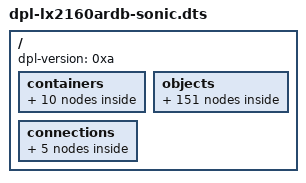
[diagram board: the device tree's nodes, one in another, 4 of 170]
/*
 * Copyright 2018-2019 NXP
 *
 * Redistribution and use in source and binary forms, with or without
 * modification, are permitted provided that the following conditions are met:
 *   * Redistributions of source code must retain the above copyright
 *     notice, this list of conditions and the following disclaimer.
 *   * Redistributions in binary form must reproduce the above copyright
 *     notice, this list of conditions and the following disclaimer in the
 *     documentation and/or other materials provided with the distribution.
 *   * Neither the name of the above-listed copyright holders nor the
 *     names of any contributors may be used to endorse or promote products
 *     derived from this software without specific prior written permission.
 *
 * THIS SOFTWARE IS PROVIDED BY THE COPYRIGHT HOLDERS AND CONTRIBUTORS "AS IS"
 * AND ANY EXPRESS OR IMPLIED WARRANTIES, INCLUDING, BUT NOT LIMITED TO, THE
 * IMPLIED WARRANTIES OF MERCHANTABILITY AND FITNESS FOR A PARTICULAR PURPOSE
 * ARE DISCLAIMED. IN NO EVENT SHALL THE COPYRIGHT HOLDERS OR CONTRIBUTORS BE
 * LIABLE FOR ANY DIRECT, INDIRECT, INCIDENTAL, SPECIAL, EXEMPLARY, OR
 * CONSEQUENTIAL DAMAGES (INCLUDING, BUT NOT LIMITED TO, PROCUREMENT OF
 * SUBSTITUTE GOODS OR SERVICES; LOSS OF USE, DATA, OR PROFITS; OR BUSINESS
 * INTERRUPTION) HOWEVER CAUSED AND ON ANY THEORY OF LIABILITY, WHETHER IN
 * CONTRACT, STRICT LIABILITY, OR TORT (INCLUDING NEGLIGENCE OR OTHERWISE)
 * ARISING IN ANY WAY OUT OF THE USE OF THIS SOFTWARE, EVEN IF ADVISED OF THE
 * POSSIBILITY OF SUCH DAMAGE.
 */

/*
 * LX2160ARDB DPL for SONiC (SerDes 19_5_2), derived from NXP mc-utils
 * dpl-eth.19.dts (lf-6.18.37-2.1.0). Changes:
 *   - dpni@2..4 added for dpmac@18 (RGMII 1G) and dpmac@3/@4 (AQR107 10GBASE-T);
 *     dpni@0 -> dpmac@17 and dpni@1 -> dpmac@2 are unchanged.
 *   - dpbp 0..5 (one buffer pool per DPNI) and dpcon 0..79 (up to 16 channels
 *     per DPNI on 16 cores), so every interface gets its full set.
 * Generated by scripts/mk-dpl.py; edit that, not this file.
 */
/dts-v1/;

/ {
	dpl-version = <0xa>;
	/*****************************************************************
	 * Containers
	 *****************************************************************/
	containers {
		dprc@1 {
			parent = "none";
			options = "DPRC_CFG_OPT_SPAWN_ALLOWED", "DPRC_CFG_OPT_ALLOC_ALLOWED", "DPRC_CFG_OPT_IRQ_CFG_ALLOWED";
			objects {
				/* ------------ DPNIs --------------*/
				obj_set@dpni {
					type = "dpni";
					ids = <0x0 0x1 0x2 0x3 0x4>;
				};


				/* ------------ DPMACs --------------*/
				obj_set@dpmac {
					type = "dpmac";
					ids = <0x2 0x3 0x4 0x5 0x6 0x11 0x12>;
				};


				/* ------------ DPBPs --------------*/
				obj_set@dpbp {
					type = "dpbp";
					ids = <0x0 0x1 0x2 0x3 0x4 0x5>;
				};

				/* ------------ DPIOs --------------*/
				obj_set@dpio {
					type = "dpio";
					ids = <0x0 0x1 0x2 0x3 0x4 0x5 0x6 0x7 0x8 0x9 0xa 0xb 0xc 0xd 0xe 0xf>;
				};

				/* ------------ DPMCPs --------------*/
				obj_set@dpmcp {
					type = "dpmcp";
					ids = <0x1 0x2 0x3 0x4 0x5 0x6 0x7 0x8 0x9 0xa 0xb 0xc 0xd 0xe 0xf 0x10 0x11 0x12 0x13 0x14 0x15 0x16 0x17 0x18 0x19 0x1a 0x1b 0x1c 0x1d 0x1e 0x1f 0x20 0x21 0x22 0x23>;
				};

				/* ------------ DPCON --------------*/
				obj_set@dpcon {
					type = "dpcon";
					ids = <0x0 0x1 0x2 0x3 0x4 0x5 0x6 0x7 0x8 0x9 0xa 0xb 0xc 0xd 0xe 0xf 0x10 0x11 0x12 0x13 0x14 0x15 0x16 0x17 0x18 0x19 0x1a 0x1b 0x1c 0x1d 0x1e 0x1f 0x20 0x21 0x22 0x23 0x24 0x25 0x26 0x27 0x28 0x29 0x2a 0x2b 0x2c 0x2d 0x2e 0x2f 0x30 0x31 0x32 0x33 0x34 0x35 0x36 0x37 0x38 0x39 0x3a 0x3b 0x3c 0x3d 0x3e 0x3f 0x40 0x41 0x42 0x43 0x44 0x45 0x46 0x47 0x48 0x49 0x4a 0x4b 0x4c 0x4d 0x4e 0x4f>;
				};

				/* ------------ DPSECI --------------*/
				obj@700 {
					obj_name = "dpseci@0";
				};

				/* ------------ DPRTC --------------*/
				obj@800 {
					obj_name="dprtc@0";
				};
			};
		};
	};

	/*****************************************************************
	 * Objects
	 *****************************************************************/
	objects {

		/* ------------ DPNI --------------*/
		dpni@0 {
			options = "";
			num_queues = <0x10>;
			num_tcs = <0x1>;
		};

		dpni@1 {
			options = "";
			num_queues = <0x10>;
			num_tcs = <0x1>;
		};


		dpni@2 {
			options = "";
			num_queues = <0x10>;
			num_tcs = <0x1>;
		};
		dpni@3 {
			options = "";
			num_queues = <0x10>;
			num_tcs = <0x1>;
		};
		dpni@4 {
			options = "";
			num_queues = <0x10>;
			num_tcs = <0x1>;
		};
		dpmac@2 {
		};

		dpmac@3 {
		};

		dpmac@4 {
		};

		dpmac@5 {
		};

		dpmac@6 {
		};

		dpmac@17 {
		};

		dpmac@18 {
		};

		/* ------------ DPBP --------------*/
		dpbp@0 {
		};

		dpbp@1 {
		};
		dpbp@2 {
		};
		dpbp@3 {
		};
		dpbp@4 {
		};
		dpbp@5 {
		};


		/* ------------ DPIO --------------*/
		dpio@0 {
			channel_mode = "DPIO_LOCAL_CHANNEL";
			num_priorities = <0x8>;
		};

		dpio@1 {
			channel_mode = "DPIO_LOCAL_CHANNEL";
			num_priorities = <0x8>;
		};

		dpio@2 {
			channel_mode = "DPIO_LOCAL_CHANNEL";
			num_priorities = <0x8>;
		};

		dpio@3 {
			channel_mode = "DPIO_LOCAL_CHANNEL";
			num_priorities = <0x8>;
		};

		dpio@4 {
			channel_mode = "DPIO_LOCAL_CHANNEL";
			num_priorities = <0x8>;
		};

		dpio@5 {
			channel_mode = "DPIO_LOCAL_CHANNEL";
			num_priorities = <0x8>;
		};

		dpio@6 {
			channel_mode = "DPIO_LOCAL_CHANNEL";
			num_priorities = <0x8>;
		};

		dpio@7 {
			channel_mode = "DPIO_LOCAL_CHANNEL";
			num_priorities = <0x8>;
		};

		dpio@8 {
			channel_mode = "DPIO_LOCAL_CHANNEL";
			num_priorities = <0x8>;
		};

		dpio@9 {
			channel_mode = "DPIO_LOCAL_CHANNEL";
			num_priorities = <0x8>;
		};

		dpio@10 {
			channel_mode = "DPIO_LOCAL_CHANNEL";
			num_priorities = <0x8>;
		};

		dpio@11 {
			channel_mode = "DPIO_LOCAL_CHANNEL";
			num_priorities = <0x8>;
		};

		dpio@12 {
			channel_mode = "DPIO_LOCAL_CHANNEL";
			num_priorities = <0x8>;
		};

		dpio@13 {
			channel_mode = "DPIO_LOCAL_CHANNEL";
			num_priorities = <0x8>;
		};

		dpio@14 {
			channel_mode = "DPIO_LOCAL_CHANNEL";
			num_priorities = <0x8>;
		};

		dpio@15 {
			channel_mode = "DPIO_LOCAL_CHANNEL";
			num_priorities = <0x8>;
		};

		/* ------------ DPMCP --------------*/
		dpmcp@1 {
		};

		dpmcp@2 {
		};

		dpmcp@3 {
		};

		dpmcp@4 {
		};

		dpmcp@5 {
		};

		dpmcp@6 {
		};

		dpmcp@7 {
		};

		dpmcp@8 {
		};

		dpmcp@9 {
		};

		dpmcp@10 {
		};

		dpmcp@11 {
		};

		dpmcp@12 {
		};

		dpmcp@13 {
		};

		dpmcp@14 {
		};

		dpmcp@15 {
		};

		dpmcp@16 {
		};

		dpmcp@17 {
		};

		dpmcp@18 {
		};

		dpmcp@19 {
		};

		dpmcp@20 {
		};

		dpmcp@21 {
		};

		dpmcp@22 {
		};

		dpmcp@23 {
		};

		dpmcp@24 {
		};

		dpmcp@25 {
		};

		dpmcp@26 {
		};

		dpmcp@27 {
		};

		dpmcp@28 {
		};

		dpmcp@29 {
		};

		dpmcp@30 {
		};

		dpmcp@31 {
		};

		dpmcp@32 {
		};

		dpmcp@33 {
		};

		dpmcp@34 {
		};

		dpmcp@35 {
		};

		/* ------------ DPCON --------------*/
		dpcon@0 {
			num_priorities = <0x2>;
		};

		dpcon@1 {
			num_priorities = <0x2>;
		};

		dpcon@2 {
			num_priorities = <0x2>;
		};

		dpcon@3 {
			num_priorities = <0x2>;
		};

		dpcon@4 {
			num_priorities = <0x2>;
		};

		dpcon@5 {
			num_priorities = <0x2>;
		};

		dpcon@6 {
			num_priorities = <0x2>;
		};

		dpcon@7 {
			num_priorities = <0x2>;
		};

		dpcon@8 {
			num_priorities = <0x2>;
		};

		dpcon@9 {
			num_priorities = <0x2>;
		};

		dpcon@10 {
			num_priorities = <0x2>;
		};

		dpcon@11 {
			num_priorities = <0x2>;
		};

		dpcon@12 {
			num_priorities = <0x2>;
		};

		dpcon@13 {
			num_priorities = <0x2>;
		};

		dpcon@14 {
			num_priorities = <0x2>;
		};

		dpcon@15 {
			num_priorities = <0x2>;
		};
		dpcon@16 {
			num_priorities = <0x2>;
		};

		dpcon@17 {
			num_priorities = <0x2>;
		};

		dpcon@18 {
			num_priorities = <0x2>;
		};

		dpcon@19 {
			num_priorities = <0x2>;
		};

		dpcon@20 {
			num_priorities = <0x2>;
		};

		dpcon@21 {
			num_priorities = <0x2>;
		};

		dpcon@22 {
			num_priorities = <0x2>;
		};

		dpcon@23 {
			num_priorities = <0x2>;
		};

		dpcon@24 {
			num_priorities = <0x2>;
		};

		dpcon@25 {
			num_priorities = <0x2>;
		};

		dpcon@26 {
			num_priorities = <0x2>;
		};

		dpcon@27 {
			num_priorities = <0x2>;
		};

		dpcon@28 {
			num_priorities = <0x2>;
		};

		dpcon@29 {
			num_priorities = <0x2>;
		};

		dpcon@30 {
			num_priorities = <0x2>;
		};

		dpcon@31 {
			num_priorities = <0x2>;
		};
		dpcon@32 {
			num_priorities = <0x2>;
		};
		dpcon@33 {
			num_priorities = <0x2>;
		};
		dpcon@34 {
			num_priorities = <0x2>;
		};
		dpcon@35 {
			num_priorities = <0x2>;
		};
		dpcon@36 {
			num_priorities = <0x2>;
		};
		dpcon@37 {
			num_priorities = <0x2>;
		};
		dpcon@38 {
			num_priorities = <0x2>;
		};
		dpcon@39 {
			num_priorities = <0x2>;
		};
		dpcon@40 {
			num_priorities = <0x2>;
		};
		dpcon@41 {
			num_priorities = <0x2>;
		};
		dpcon@42 {
			num_priorities = <0x2>;
		};
		dpcon@43 {
			num_priorities = <0x2>;
		};
		dpcon@44 {
			num_priorities = <0x2>;
		};
		dpcon@45 {
			num_priorities = <0x2>;
		};
		dpcon@46 {
			num_priorities = <0x2>;
		};
		dpcon@47 {
			num_priorities = <0x2>;
		};
		dpcon@48 {
			num_priorities = <0x2>;
		};
		dpcon@49 {
			num_priorities = <0x2>;
		};
		dpcon@50 {
			num_priorities = <0x2>;
		};
		dpcon@51 {
			num_priorities = <0x2>;
		};
		dpcon@52 {
			num_priorities = <0x2>;
		};
		dpcon@53 {
			num_priorities = <0x2>;
		};
		dpcon@54 {
			num_priorities = <0x2>;
		};
		dpcon@55 {
			num_priorities = <0x2>;
		};
		dpcon@56 {
			num_priorities = <0x2>;
		};
		dpcon@57 {
			num_priorities = <0x2>;
		};
		dpcon@58 {
			num_priorities = <0x2>;
		};
		dpcon@59 {
			num_priorities = <0x2>;
		};
		dpcon@60 {
			num_priorities = <0x2>;
		};
		dpcon@61 {
			num_priorities = <0x2>;
		};
		dpcon@62 {
			num_priorities = <0x2>;
		};
		dpcon@63 {
			num_priorities = <0x2>;
		};
		dpcon@64 {
			num_priorities = <0x2>;
		};
		dpcon@65 {
			num_priorities = <0x2>;
		};
		dpcon@66 {
			num_priorities = <0x2>;
		};
		dpcon@67 {
			num_priorities = <0x2>;
		};
		dpcon@68 {
			num_priorities = <0x2>;
		};
		dpcon@69 {
			num_priorities = <0x2>;
		};
		dpcon@70 {
			num_priorities = <0x2>;
		};
		dpcon@71 {
			num_priorities = <0x2>;
		};
		dpcon@72 {
			num_priorities = <0x2>;
		};
		dpcon@73 {
			num_priorities = <0x2>;
		};
		dpcon@74 {
			num_priorities = <0x2>;
		};
		dpcon@75 {
			num_priorities = <0x2>;
		};
		dpcon@76 {
			num_priorities = <0x2>;
		};
		dpcon@77 {
			num_priorities = <0x2>;
		};
		dpcon@78 {
			num_priorities = <0x2>;
		};
		dpcon@79 {
			num_priorities = <0x2>;
		};

		/* ------------ DPSECI --------------*/
		dpseci@0 {
			priorities = <0x01 0x01 0x01 0x01 0x01 0x01 0x01 0x01 0x01 0x01 0x01 0x01 0x01 0x01 0x01 0x01>;
			options = "DPSECI_OPT_HAS_CG";
		};

		/* ------------ DPRTC --------------*/
		dprtc@0 {
			compatible="fsl,dprtc";
		};
	};

	/*****************************************************************
	 * Connections
	 *****************************************************************/
	connections {
		connection@1 {
			endpoint1 = "dpni@0";
			endpoint2 = "dpmac@17";
		};

		connection@2 {
			endpoint1 = "dpni@1";
			endpoint2 = "dpmac@2";
		};
		connection@3 {
			endpoint1 = "dpni@2";
			endpoint2 = "dpmac@18";
		};
		connection@4 {
			endpoint1 = "dpni@3";
			endpoint2 = "dpmac@3";
		};
		connection@5 {
			endpoint1 = "dpni@4";
			endpoint2 = "dpmac@4";
		};

	};
};

